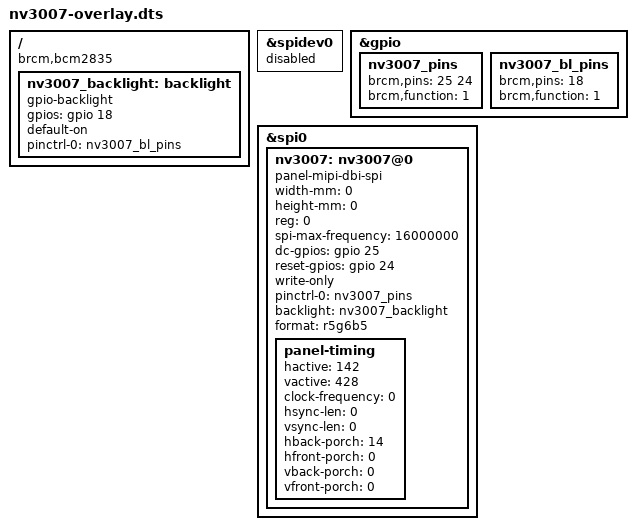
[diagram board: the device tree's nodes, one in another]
/*
 * nv3007-overlay.dts - solar-ctl
 *
 * 2.79" NV3007 TFT (TZT 142x428 8-pin SPI module). Driven by the
 * generic panel-mipi-dbi driver (NOT ili9341 - that one hardcodes
 * 240x320). The mode comes from the panel-timing node below; the
 * controller init sequence comes from the firmware file
 * /lib/firmware/panel-mipi-dbi-spi.bin, shipped by the solar-panel-fw
 * recipe (generated by fw/tools/lvgl-nv3007-to-mipi-dbi.py).
 *
 * solar-ctl wiring (defaults; overridable on the dtoverlay= line):
 *   MOSI  GPIO10  (P1-19)
 *   SCLK  GPIO11  (P1-23)
 *   CE0   GPIO8   (P1-24)   SPI0 enabled by this overlay
 *   DC    GPIO25  (P1-22)   dc_pin=<n>
 *   RST   GPIO24  (P1-18)   reset_pin=<n>
 *   BLK   GPIO18  (P1-12)   led_pin=<n>   (gpio-backlight, default-on)
 *   VCC   3V3, GND
 *
 * Panel is native portrait 142x428; framebuffer /dev/fb0 (DRM fbdev
 * emulation). mipi-dbi has no DT rotation property - see fw/README.md
 * "Orientation" for the two supported ways to rotate.
 *
 * Enable in config.txt:  dtoverlay=nv3007
 */

/dts-v1/;
/plugin/;

#include <dt-bindings/gpio/gpio.h>

/ {
	compatible = "brcm,bcm2835";

	fragment@0 {
		target = <&spidev0>;
		__overlay__ {
			status = "disabled";
		};
	};

	fragment@1 {
		target = <&gpio>;
		__overlay__ {
			nv3007_pins: nv3007_pins {
				brcm,pins = <25 24>;
				brcm,function = <1>; /* out */
			};
			nv3007_bl_pins: nv3007_bl_pins {
				brcm,pins = <18>;
				brcm,function = <1>; /* out */
			};
		};
	};

	fragment@2 {
		target-path = "/";
		__overlay__ {
			nv3007_backlight: backlight {
				compatible = "gpio-backlight";
				gpios = <&gpio 18 GPIO_ACTIVE_HIGH>;
				default-on;
				pinctrl-names = "default";
				pinctrl-0 = <&nv3007_bl_pins>;
			};
		};
	};

	fragment@3 {
		target = <&spi0>;
		__overlay__ {
			/* needed to avoid dtc warning */
			#address-cells = <1>;
			#size-cells = <0>;
			status = "okay";

			nv3007: nv3007@0 {
				compatible = "panel-mipi-dbi-spi";
				/* panel-mipi-dbi requires these two props
				   (0 = "unknown size" is legal) */
				width-mm = <0>;
				height-mm = <0>;
				reg = <0>;
				/* panel spec is 32 MHz; 16 MHz default leaves margin
				   for flying leads (bench ran 2 MHz error-free) -
				   override: dtoverlay=nv3007,speed=<Hz> */
				spi-max-frequency = <16000000>;
				dc-gpios = <&gpio 25 GPIO_ACTIVE_HIGH>;
				/* ACTIVE_HIGH is correct: kernel hw_reset idles
				   the line physical-HIGH, pulses ~20us LOW —
				   which matches the module's active-low RES */
				reset-gpios = <&gpio 24 GPIO_ACTIVE_HIGH>;
				/* module is write-only: 8-pin header carries no MISO,
				   so reads must not be attempted (would gate init) */
				write-only;
				pinctrl-names = "default";
				pinctrl-0 = <&nv3007_pins>;
				backlight = <&nv3007_backlight>;
				/* 16-bit pixel bus, init sequence via firmware
				   file (no native 18-bit mode on this module) */
				format = "r5g6b5";
				status = "okay";

				/* panel-mipi-dbi binding: hactive/vactive are
				   the whole resolution; hsync/vsync lenses
				   and front porches must be 0 (nonzero =
				   "panel-timing out of bounds"). hback-porch
				   is the X offset and vback-porch the Y
				   offset of the visible window inside the
				   controller GRAM: bench-measured kx=14 for
				   this TZT module (removes a stale-pixel
				   column band), ky=0 (red/blue edge rows sat
				   exactly at both ends). clock-frequency 0 =
				   driver fakes one (unused over SPI). */
				panel-timing {
					hactive = <142>;
					vactive = <428>;
					clock-frequency = <0>;
					hsync-len = <0>;
					vsync-len = <0>;
					hback-porch = <14>;
					hfront-porch = <0>;
					vback-porch = <0>;
					vfront-porch = <0>;
				};
			};
		};
	};

	__overrides__ {
		speed = <&nv3007>, "spi-max-frequency:0";
		dc_pin = <&nv3007>, "dc-gpios:4",
			 <&nv3007_pins>, "brcm,pins:0";
		reset_pin = <&nv3007>, "reset-gpios:4",
			    <&nv3007_pins>, "brcm,pins:4";
		led_pin = <&nv3007_backlight>, "gpios:4",
			  <&nv3007_bl_pins>, "brcm,pins:0";
	};
};
